# A34L71x register map
Vendor: ABOV Semiconductor Co., Ltd.; File version: 1.0
CPU: CM4 r0p1, little endian, MPU, FPU, VTOR, 4 interrupt priority bits
Registers are 32-bit, read-write, reset 0x0 unless marked. A register's access mark holds for its fields unless they carry their own. Offsets are from the block's base; [hi:lo] are bit positions; {n}, {i} and the like mark numbered series.

## FRT — Free Run Timer
Base 0x40000600
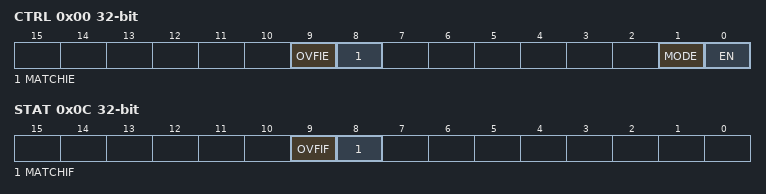
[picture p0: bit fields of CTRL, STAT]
0x00 CTRL — FRT control register
  [9] OVFIE — Whether to enable or disable the FRT counter overflow interrupt in Free-run timer mode (MODE = 0)
    0=Disable (Interrupt Disable); 1=Enable (Interrupt Enable)
  [8] MATCHIE — Whether to enable or disable the FRT counter match interrupt in Periodic timer mode (MODE = 1)
    0=Disable (Interrupt Disable); 1=Enable (Interrupt Enable)
  [1] MODE — FRT mode selection
    0=Free-Run_Timer; 1=Match_Timer
  [0] EN — Whether to enable or disable the FRT
    0=Disable (FRT Disable); 1=Enable (FRT Enable)
0x04 MCNT reset 0xFFFFFFFF — FRT match counter register
  [31:0] MCNT — FRTs match counter value
0x08 CNT — FRT counter register
  [31:0] CNT — FRT count data
0x0C STAT — FRT status register
  [9] OVFIF — FRT counter overflow interrupt flag
  [8] MATCHIF — Whether to enable or disable the FRT counter match interrupt in Periodic timer mode (MODE = 1)

## UART — Universal Asynchronous Receiver/Transmitter
Base 0x40008000
0x00 RBR ro — UART n receive data buffer register
  [7:0] RBR — Receive buffer register
0x00 THR wo — UART n transmit data hold register
  [7:0] THR — Transmit data hold register
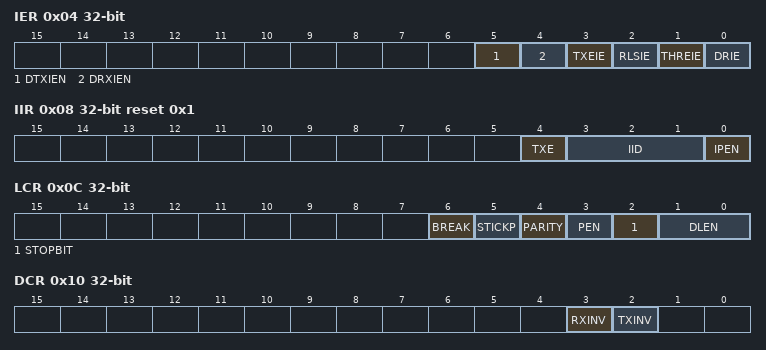
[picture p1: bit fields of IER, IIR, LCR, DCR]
0x04 IER — UART n interrupt enable register
  [5] DTXIEN — Whether to enable or disable the DMA transmit complete interrupt
  [4] DRXIEN — Whether to enable or disable the DMA receive complete interrupt
  [3] TXEIE — Whether to enable or disable the transmit complete interrupt
  [2] RLSIE — Whether to enable or disable the receive line status interrupt
  [1] THREIE — Whether to enable or disable the transmit data hold register empty (THRE) interrupt
  [0] DRIE — Whether to enable or disable the data receive interrupt
0x08 IIR ro reset 0x1 — UART n interrupt ID register
  [4] TXE — Transmit complete
  [3:1] IID — Interrupt source ID
  [0] IPEN — Presence of pending interrupts
0x0C LCR — UART n line control register
  [6] BREAK — When this bit is set to 1, the TXD pin is driven low to alert the receiver
  [5] STICKP — Whether or not to use stick parity. The setting of this bit is valid only when the PEN bit is set to 1
  [4] PARITY — Parity mode selection
  [3] PEN — Whether or not to enable parity
  [2] STOPBIT — The number of stop bits demanded by the preceding data bits
  [1:0] DLEN — The length of data bits included by each data transfer
    {v}={v+5}bit data (v=0..3)
0x10 DCR — UART n data control register
  [3] RXINV — Rx data inversion selection
  [2] TXINV — Tx data inversion selection
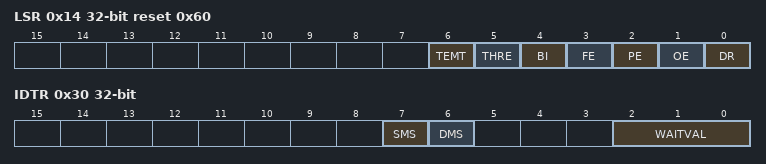
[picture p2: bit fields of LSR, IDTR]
0x14 LSR ro reset 0x60 — UART n line status register
  [6] TEMT — Whether or not the transmit registers are empty
  [5] THRE — Whether or not the transmit data hold register is empty
  [4] BI — Whether or not a break condition has been detected
  [3] FE — Presence of a frame error
  [2] PE — Presence of a parity error
  [1] OE — Presence of an overrun error
  [0] DR — Data reception status
0x20 BDR — UART n baud-rate divisor latch register
  [15:0] BDR — Baud-rate divisor latch (1 to 65535)
0x24 BFR — UART n baud-rate fraction counter register
  [7:0] BFR — Whether to enable or disable the fraction counter to compensate error from the integer baud-rate divisor
0x30 IDTR — UARTn Inter-frame Delay Time Register
  [7] SMS — Whether to enable or disable multi-sampling the start bit
  [6] DMS — Whether to enable or disable multi-sampling each data bit
  [2:0] WAITVAL — Defines the wait time for the next data frame. [unit: 1-bit period]

## SPI — Serial Peripheral Interface Bus
Base 0x50009000
Same registers: SPI0 0x40009000, SPI1 0x40009100
0x00 TDR wo — SPI transmit data register
  [16:0] TDR — Transmit data register
0x00 RDR ro — SPI receive data register
  [16:0] RDR — Receive data register
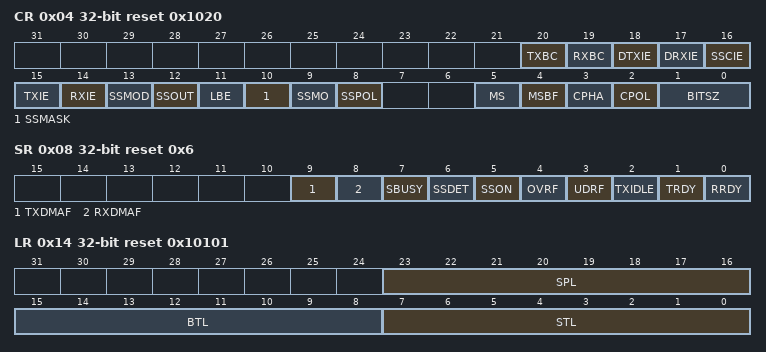
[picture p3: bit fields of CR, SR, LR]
0x04 CR reset 0x1020 — SPI control register
  [20] TXBC — Tx buffer clear bit. (Auto-clear)
  [19] RXBC — Rx buffer clear bit. (Auto-clear)
  [18] DTXIE — DMA Tx done interrupt enable bit.
  [17] DRXIE — DMA Rx done interrupt enable bit.
  [16] SSCIE — SS edge change interrupt enable bit.
  [15] TXIE — Transmit interrupt enable bit.
  [14] RXIE — Received Interrupt Enable Bit
  [13] SSMOD — SS auto / manual output select bit.
  [12] SSOUT — SS output signal select bit
  [11] LBE — Loop-back mode select bit in master mode
  [10] SSMASK — SS signal masking bit in slave mode
  [9] SSMO — SS output signal select bit
  [8] SSPOL — SS signal polarity select bit
  [5] MS — Master / Slave select bit
  [4] MSBF — MSB / LSB transmit select bit
  [3] CPHA — SPI clock phase bit
  [2] CPOL — SPI clock polarity bit
  [1:0] BITSZ — Transmit / Receive data bits select bit
    0=8_BIT (Size is 8 bit); 1=9_BIT (Size is 9 bit); 2=16_BIT (Size is 16 bit); 3=17_BIT (Size is 17 bit)
0x08 SR reset 0x6 — SPI status register
  [9] TXDMAF — DMA Transmit Operation Complete flag. (DMA to SPI)
  [8] RXDMAF — DMA receive operation complete flag. (SPI to DMA)
  [7] SBUSY ro — Transmit or receive flag
  [6] SSDET — The rising or falling edge of SS signal detect flag
  [5] SSON — SS signal Status flag
  [4] OVRF — Receive overrun error flag
  [3] UDRF — Transmit underrun error flag
  [2] TXIDLE ro — Transmit / receive operation flag
  [1] TRDY ro — Transmit buffer empty flag
  [0] RRDY ro — Receive buffer ready flag
0x0C BR reset 0xFFFF — SPI baud-rate register
  [15:0] BR — Baud-rate setting bits
0x10 EN — SPI enable register
  [0] ENABLE — SPI enable bit
0x14 LR reset 0x10101 — SPI delay length register
  [23:16] SPL — Stop length value
  [15:8] BTL — Burst length value
  [7:0] STL — Start length value
